# N32L436 register map
Vendor: Nationstech Ltd.; File version: 1.0
Registers are 32-bit, read-write, reset 0x0 unless marked. A register's access mark holds for its fields unless they carry their own. Offsets are from the block's base; [hi:lo] are bit positions; {n}, {i} and the like mark numbered series.

## LPUART — Low-power universal asynchronous receiver transmitter
Base 0x40005000
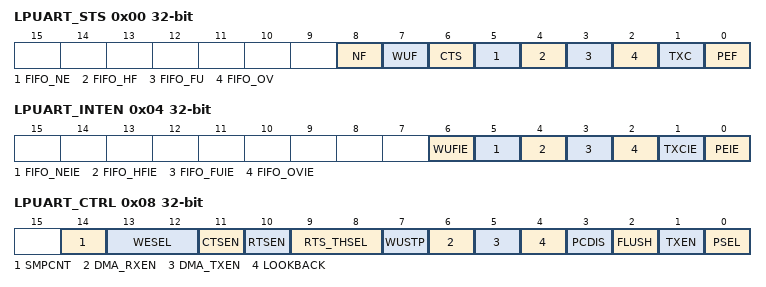
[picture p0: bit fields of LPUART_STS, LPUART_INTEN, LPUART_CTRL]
0x00 LPUART_STS
  [8] NF, [7] WUF, [6] CTS, [5] FIFO_NE, [4] FIFO_HF, [3] FIFO_FU, [2] FIFO_OV, [1] TXC, [0] PEF
0x04 LPUART_INTEN
  [6] WUFIE, [5] FIFO_NEIE, [4] FIFO_HFIE, [3] FIFO_FUIE, [2] FIFO_OVIE, [1] TXCIE, [0] PEIE
0x08 LPUART_CTRL
  [14] SMPCNT, [13:12] WESEL, [11] CTSEN, [10] RTSEN, [9:8] RTS_THSEL, [7] WUSTP, [6] DMA_RXEN, [5] DMA_TXEN, [4] LOOKBACK, [3] PCDIS, [2] FLUSH, [1] TXEN, [0] PSEL
0x0C LPUART_BRCFG1 reset 0x174
  [15:0] INTEGER
0x10 LPUART_DAT
  [7:0] DAT
0x14 LPUART_BRCFG2
  [7:0] DECIMAL
0x18 LPUART_WUDAT

## OPAMP — operational amplifier
Base 0x40002000
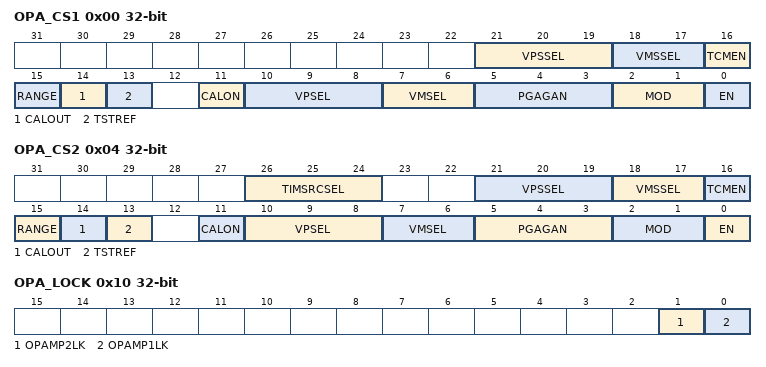
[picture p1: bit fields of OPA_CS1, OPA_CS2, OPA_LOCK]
0x00 OPA_CS1
  [21:19] VPSSEL, [18:17] VMSSEL, [16] TCMEN, [15] RANGE, [14] CALOUT, [13] TSTREF, [11] CALON, [10:8] VPSEL, [7:6] VMSEL, [5:3] PGAGAN, [2:1] MOD, [0] EN
0x04 OPA_CS2 (reset mask 0x3FFFFF)
  [26:24] TIMSRCSEL, [21:19] VPSSEL, [18:17] VMSSEL, [16] TCMEN, [15] RANGE, [14] CALOUT, [13] TSTREF, [11] CALON, [10:8] VPSEL, [7:6] VMSEL, [5:3] PGAGAN, [2:1] MOD, [0] EN
0x10 OPA_LOCK
  [1] OPAMP2LK, [0] OPAMP1LK

## PWR — Power control
Base 0x40007000
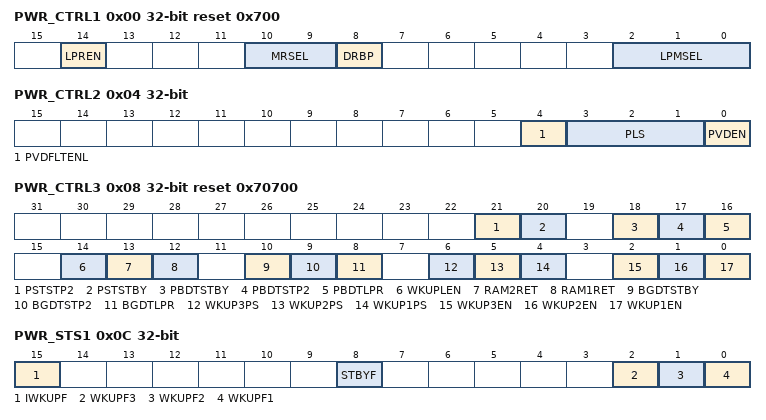
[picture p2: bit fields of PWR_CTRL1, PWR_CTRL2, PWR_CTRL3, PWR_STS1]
0x00 PWR_CTRL1 reset 0x700 — PWR_CTRL
  [14] LPREN, [10:9] MRSEL, [8] DRBP, [2:0] LPMSEL
0x04 PWR_CTRL2 — PWR_CTRL
  [4] PVDFLTENL — PVDFLTEN
  [3:1] PLS
  [0] PVDEN
0x08 PWR_CTRL3 reset 0x70700 (reset mask 0x37777) — PWR_CTRL
  [21] PSTSTP2, [20] PSTSTBY, [18] PBDTSTBY, [17] PBDTSTP2, [16] PBDTLPR, [14] WKUPLEN, [13] RAM2RET, [12] RAM1RET, [10] BGDTSTBY, [9] BGDTSTP2, [8] BGDTLPR, [6] WKUP3PS, [5] WKUP2PS, [4] WKUP1PS, [2] WKUP3EN, [1] WKUP2EN, [0] WKUP1EN
0x0C PWR_STS1 read — PWR_STS
  [15] IWKUPF, [8] STBYF, [2] WKUPF3, [1] WKUPF2, [0] WKUPF1
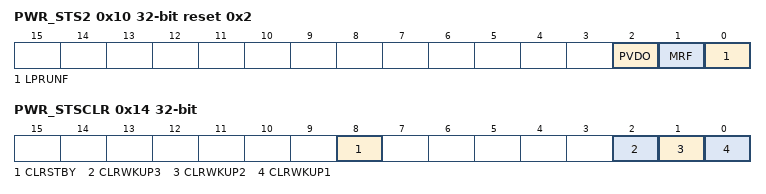
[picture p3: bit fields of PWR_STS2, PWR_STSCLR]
0x10 PWR_STS2 read reset 0x2 — PWR_STS
  [2] PVDO, [1] MRF, [0] LPRUNF
0x14 PWR_STSCLR write
  [8] CLRSTBY, [2] CLRWKUP3, [1] CLRWKUP2, [0] CLRWKUP1

## RCC — Reset and clock control
Base 0x40021000
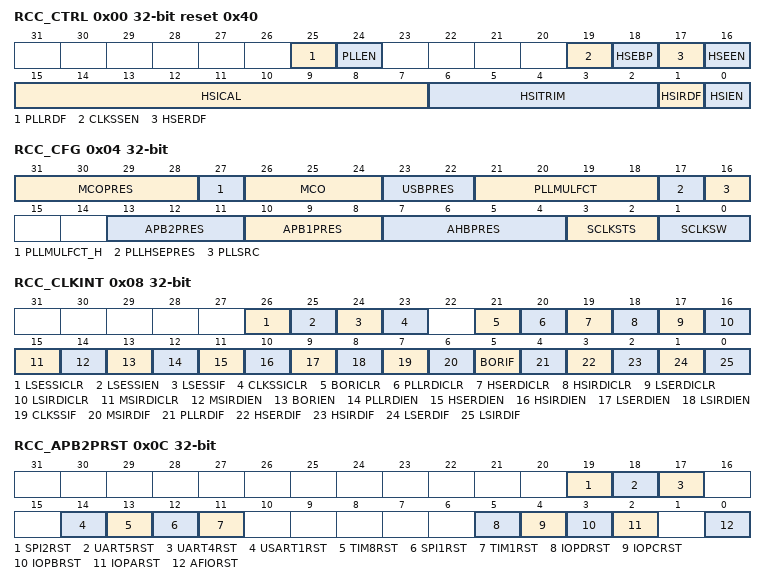
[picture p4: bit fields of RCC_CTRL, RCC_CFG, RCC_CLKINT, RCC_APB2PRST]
0x00 RCC_CTRL reset 0x40
  [25] PLLRDF, [24] PLLEN, [19] CLKSSEN, [18] HSEBP, [17] HSERDF, [16] HSEEN, [15:7] HSICAL, [6:2] HSITRIM, [1] HSIRDF, [0] HSIEN
0x04 RCC_CFG
  [31:28] MCOPRES, [27] PLLMULFCT_H, [26:24] MCO, [23:22] USBPRES, [21:18] PLLMULFCT, [17] PLLHSEPRES, [16] PLLSRC, [13:11] APB2PRES, [10:8] APB1PRES, [7:4] AHBPRES, [3:2] SCLKSTS, [1:0] SCLKSW
0x08 RCC_CLKINT
  [26] LSESSICLR, [25] LSESSIEN, [24] LSESSIF, [23] CLKSSICLR, [21] BORICLR, [20] PLLRDICLR, [19] HSERDICLR, [18] HSIRDICLR, [17] LSERDICLR, [16] LSIRDICLR, [15] MSIRDICLR, [14] MSIRDIEN, [13] BORIEN, [12] PLLRDIEN, [11] HSERDIEN, [10] HSIRDIEN, [9] LSERDIEN, [8] LSIRDIEN, [7] CLKSSIF, [6] MSIRDIF, [5] BORIF, [4] PLLRDIF, [3] HSERDIF, [2] HSIRDIF, [1] LSERDIF, [0] LSIRDIF
0x0C RCC_APB2PRST
  [19] SPI2RST, [18] UART5RST, [17] UART4RST, [14] USART1RST, [13] TIM8RST, [12] SPI1RST, [11] TIM1RST, [5] IOPDRST, [4] IOPCRST, [3] IOPBRST, [2] IOPARST, [0] AFIORST
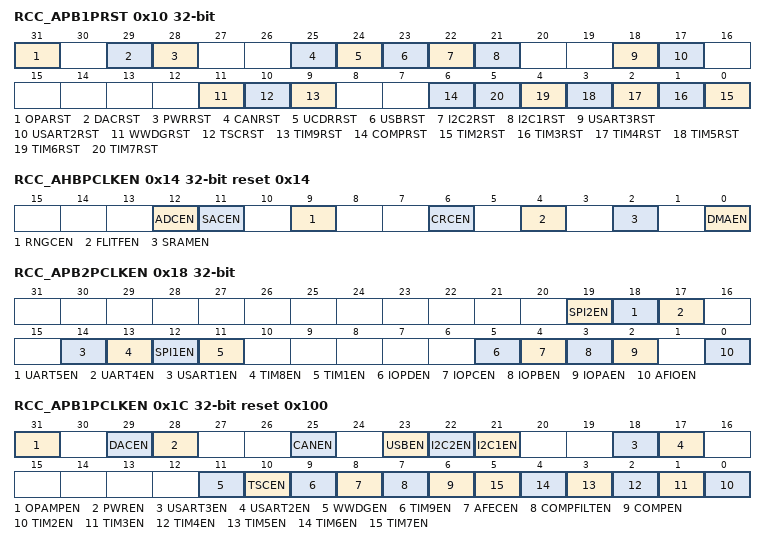
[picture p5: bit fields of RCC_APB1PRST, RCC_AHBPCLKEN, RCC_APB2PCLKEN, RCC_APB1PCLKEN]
0x10 RCC_APB1PRST
  [31] OPARST, [29] DACRST, [28] PWRRST, [25] CANRST, [24] UCDRRST, [23] USBRST, [22] I2C2RST, [21] I2C1RST, [18] USART3RST, [17] USART2RST, [11] WWDGRST, [10] TSCRST, [9] TIM9RST, [6] COMPRST, [n-2] TIM{n}RST (n=2..7)
0x14 RCC_AHBPCLKEN reset 0x14
  [12] ADCEN, [11] SACEN, [9] RNGCEN, [6] CRCEN, [4] FLITFEN, [2] SRAMEN, [0] DMAEN
0x18 RCC_APB2PCLKEN
  [19] SPI2EN, [18] UART5EN, [17] UART4EN, [14] USART1EN, [13] TIM8EN, [12] SPI1EN, [11] TIM1EN, [5] IOPDEN, [4] IOPCEN, [3] IOPBEN, [2] IOPAEN, [0] AFIOEN
0x1C RCC_APB1PCLKEN reset 0x100 (reset mask 0xB3E60E7F)
  [31] OPAMPEN, [29] DACEN, [28] PWREN, [25] CANEN, [23] USBEN, [22] I2C2EN, [21] I2C1EN, [18] USART3EN, [17] USART2EN, [11] WWDGEN, [10] TSCEN, [9] TIM9EN, [8] AFECEN, [7] COMPFILTEN, [6] COMPEN, [n-2] TIM{n}EN (n=2..7)
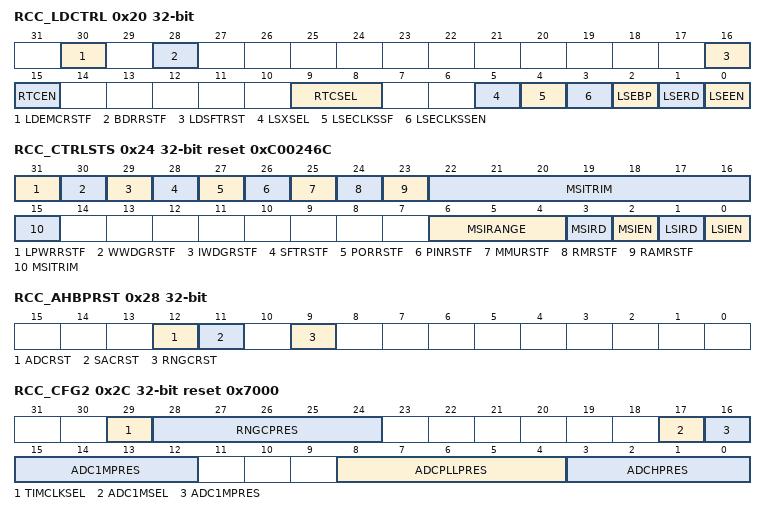
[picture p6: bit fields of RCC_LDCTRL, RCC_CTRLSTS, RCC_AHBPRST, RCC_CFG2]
0x20 RCC_LDCTRL
  [30] LDEMCRSTF, [28] BDRRSTF, [16] LDSFTRST, [15] RTCEN, [9:8] RTCSEL, [5] LSXSEL, [4] LSECLKSSF, [3] LSECLKSSEN, [2] LSEBP, [1] LSERD, [0] LSEEN
0x24 RCC_CTRLSTS reset 0xC00246C
  [31] LPWRRSTF, [30] WWDGRSTF, [29] IWDGRSTF, [28] SFTRSTF, [27] PORRSTF, [26] PINRSTF, [25] MMURSTF, [24] RMRSTF, [23] RAMRSTF, [22:15] MSITRIM, [6:4] MSIRANGE, [3] MSIRD, [2] MSIEN, [1] LSIRD, [0] LSIEN
0x28 RCC_AHBPRST
  [12] ADCRST, [11] SACRST, [9] RNGCRST
0x2C RCC_CFG2 reset 0x7000
  [29] TIMCLKSEL, [28:24] RNGCPRES, [17] ADC1MSEL, [16:12] ADC1MPRES, [8:4] ADCPLLPRES, [3:0] ADCHPRES
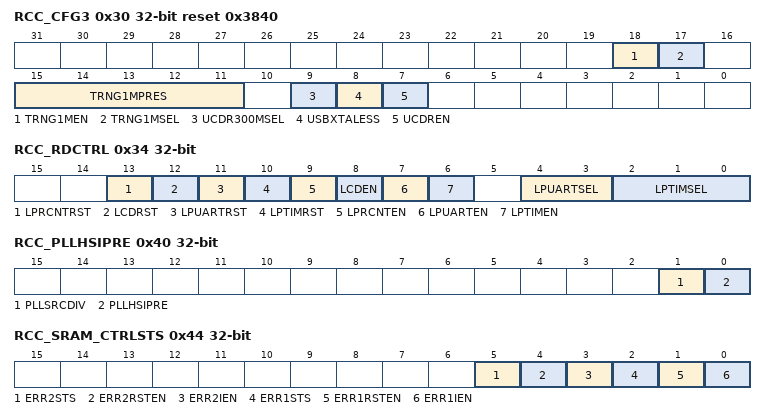
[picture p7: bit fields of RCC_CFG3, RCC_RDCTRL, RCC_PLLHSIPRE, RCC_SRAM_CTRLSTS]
0x30 RCC_CFG3 reset 0x3840
  [18] TRNG1MEN, [17] TRNG1MSEL, [15:11] TRNG1MPRES, [9] UCDR300MSEL, [8] USBXTALESS, [7] UCDREN
0x34 RCC_RDCTRL
  [13] LPRCNTRST, [12] LCDRST, [11] LPUARTRST, [10] LPTIMRST, [9] LPRCNTEN, [8] LCDEN, [7] LPUARTEN, [6] LPTIMEN, [4:3] LPUARTSEL, [2:0] LPTIMSEL
0x40 RCC_PLLHSIPRE
  [1] PLLSRCDIV, [0] PLLHSIPRE
0x44 RCC_SRAM_CTRLSTS
  [5] ERR2STS — ERR1STS
  [4] ERR2RSTEN — ERR1RSTEN
  [3] ERR2IEN — ERR1IEN
  [2] ERR1STS
  [1] ERR1RSTEN
  [0] ERR1IEN
